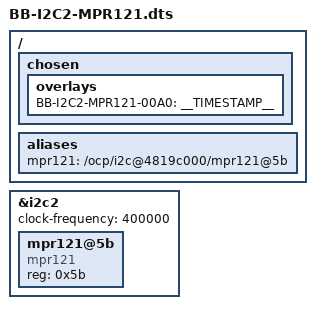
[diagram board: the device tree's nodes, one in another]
/*
 * Copyright (C) 2020 Seeed Studio
 * Baozhu Zuo <zuobaozhu@gmail.com>
 *
 * MIT License
 *
 */
/dts-v1/;
/plugin/;

/ {
	/*
	 * Helper to show loaded overlays under: /proc/device-tree/chosen/overlays/
	 */
	fragment@0 {
		target-path="/";
		__overlay__ {
			chosen {
				overlays {
					BB-I2C2-MPR121-00A0 = __TIMESTAMP__;
				};
			};
		};
	};

	fragment@1 {
		target-path="/";
		__overlay__ {

			aliases {
				/* SLOT I2C1 */
				/*
				mpr121 = "/ocp/i2c@4802a000/mpr121@5b";
				*/
				/* SLOT I2C2 */
				mpr121 = "/ocp/i2c@4819c000/mpr121@5b";
			};
		};
	};

	fragment@2 {
		/* SLOT I2C1 */
		/*
		target = <&i2c1>;
		*/
		/* SLOT I2C2 */
		target = <&i2c2>;

		__overlay__ {
			status = "okay";

			clock-frequency = <400000>;

			#address-cells = <1>;
			#size-cells = <0>;

			mpr121@5b {
                compatible = "mpr121";
                reg = <0x5b>;
                status = "okay";
		    };
        };
	};
};

